VERSION "CANLab demo 1.0"
NS_ :

BS_:

BU_: ECU BodyECU Charger Tester

// ---------------------------------------------------------------------------
// A valid database.  Nothing in here conflicts, so every mismatch that
// CANLab reports against it points at the *frame*, not at the definition.
//
// 0x100 covers all 64 bits exactly once:
//   Counter      0..7    Intel unsigned
//   Speed        8..23   Intel unsigned, scale 0.01
//   CoolantTemp  24..31  Intel signed, offset -40
//   EngineTorque 32..47  Motorola signed, start bit 39 (MSB), scale 0.5
//   AuxFlags     48..51  Intel, 4 bits of independent flags
//   ThrottlePct  52..59  Intel, scale 0.4
//   LampState    60..63  Intel, text enum
// ---------------------------------------------------------------------------
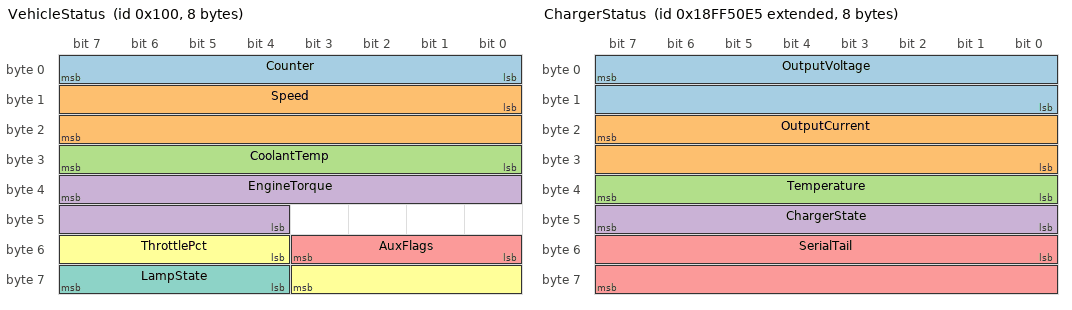
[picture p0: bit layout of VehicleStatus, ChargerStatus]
BO_ 256 VehicleStatus: 8 ECU
 SG_ Counter : 0|8@1+ (1,0) [0|255] "" BodyECU
 SG_ Speed : 8|16@1+ (0.01,0) [0|655.35] "km/h" BodyECU
 SG_ CoolantTemp : 24|8@1+ (1,-40) [-40|215] "degC" BodyECU
 SG_ EngineTorque : 39|12@0- (0.5,0) [-1000|1000] "Nm" BodyECU
 SG_ AuxFlags : 48|4@1+ (1,0) [0|15] "" BodyECU
 SG_ ThrottlePct : 52|8@1+ (0.4,0) [0|100] "%" BodyECU
 SG_ LampState : 60|4@1+ (1,0) [0|15] "" BodyECU

// Mode=0 "Idle" selects no branch: every m* signal is not applicable.
// Mode=1 and Mode=2 branches reuse the same bytes, which is legal because
// they are mutually exclusive.  Mode=3 has a single 32-bit service value.
BO_ 257 BodyCommand: 8 BodyECU
 SG_ Mode M : 0|8@1+ (1,0) [0|3] "" ECU
 SG_ MotorRpm m1 : 8|16@1- (1,0) [-20000|20000] "rpm" ECU
 SG_ MotorCurrent m1 : 24|12@1+ (0.1,-100) [-100|309.5] "A" ECU
 SG_ ChargeVoltage m2 : 8|16@1+ (0.05,0) [0|800] "V" ECU
 SG_ ChargeTimer m2 : 24|16@1+ (1,0) [0|65535] "min" ECU
 SG_ ServiceCode m3 : 8|32@1+ (1,0) [0|4294967295] "" ECU
 SG_ Heartbeat : 56|8@1+ (1,0) [0|255] "" ECU

// Nested multiplexing, expressed with SG_MUL_VAL_ because the plain
// m<id> marker cannot name the parent selector.
//   Group=1 -> Sub is read;  Sub=2 -> LeafA;  Sub=3 -> LeafB
BO_ 258 DiagNested: 8 BodyECU
 SG_ Group M : 0|4@1+ (1,0) [0|15] "" ECU
 SG_ Sub m1M : 4|4@1+ (1,0) [0|15] "" ECU
 SG_ LeafA m2 : 8|8@1+ (1,0) [0|255] "" ECU
 SG_ LeafB m3 : 8|8@1+ (1,0) [0|255] "" ECU
 SG_ PlainGroup : 16|8@1+ (1,0) [0|255] "" ECU
 SG_ Heartbeat : 56|8@1+ (1,0) [0|255] "" ECU

BO_ 259 FreeCounter: 8 Tester
 SG_ Ticks : 0|32@1+ (1,0) [0|4294967295] "" ECU
 SG_ Note : 32|8@1+ (1,0) [0|255] "" ECU

// 29-bit extended frame (0x18FF50E5).  The high bit in the DBC id marks it.
// Both voltage and current are Motorola, so the start bit is the MSB.
BO_ 2566869221 ChargerStatus: 8 Charger
 SG_ OutputVoltage : 7|16@0+ (0.1,0) [0|800] "V" ECU
 SG_ OutputCurrent : 23|16@0- (0.01,0) [-500|500] "A" ECU
 SG_ Temperature : 32|8@1+ (1,-40) [-40|215] "degC" ECU
 SG_ ChargerState : 40|8@1+ (1,0) [0|3] "" ECU
 SG_ SerialTail : 48|16@1+ (1,0) [0|65535] "" ECU

SG_MUL_VAL_ 258 Sub Group 1-1;
SG_MUL_VAL_ 258 LeafA Sub 2-2;
SG_MUL_VAL_ 258 LeafB Sub 3-3;

VAL_ 256 LampState 0 "Off" 1 "On" 2 "Blink" 3 "Fault" ;
VAL_ 256 AuxFlags 0 "None" 5 "HighBeam+RearFog" 15 "AllOn" ;
VAL_ 257 Mode 0 "Idle" 1 "Drive" 2 "Charge" 3 "Service" ;
VAL_ 2566869221 ChargerState 0 "Standby" 1 "Charging" 2 "Complete" 3 "Fault" ;

CM_ BO_ 256 "Body status frame. EngineTorque is Motorola (start bit 39 is its MSB); everything else is Intel.";
CM_ BO_ 257 "Multiplexed command frame. Mode=0 selects no branch on purpose: every m* signal is then not applicable, not zero.";
CM_ SG_ 257 MotorCurrent "Physical = raw * 0.1 - 100; raw 1000 means 0 A.";
CM_ BO_ 258 "Nested multiplexing: Group=1 exposes Sub; Sub=2 selects LeafA, Sub=3 selects LeafB.";
